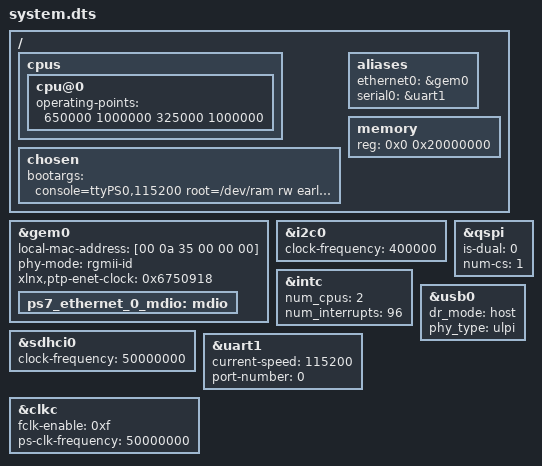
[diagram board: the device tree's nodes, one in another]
/*
 * CAUTION: This file is automatically generated by Xilinx.
 * Version:  
 * Today is: Wed Jul  8 15:01:53 2015
*/


/dts-v1/;
/include/ "zynq-7000.dtsi"
/include/ "pl.dtsi"
/ {
	cpus {
		cpu@0 {
			operating-points = <650000 1000000 325000 1000000>;
		};
	};
	chosen {
		bootargs = "console=ttyPS0,115200 root=/dev/ram rw earlyprintk";
	};
	aliases {
		ethernet0 = &gem0;
		serial0 = &uart1;
	};
	memory {
		device_type = "memory";
		reg = <0x0 0x20000000>;
	};
};
&gem0 {
	local-mac-address = [00 0a 35 00 00 00];
	phy-mode = "rgmii-id";
	status = "okay";
	xlnx,ptp-enet-clock = <0x6750918>;
	ps7_ethernet_0_mdio: mdio {
		#address-cells = <1>;
		#size-cells = <0>;
	};
};
&i2c0 {
	clock-frequency = <400000>;
	status = "okay";
};
&intc {
	num_cpus = <2>;
	num_interrupts = <96>;
};
&qspi {
	is-dual = <0>;
	num-cs = <1>;
	status = "okay";
};
&sdhci0 {
	clock-frequency = <50000000>;
	status = "okay";
};
&uart1 {
	current-speed = <115200>;
	device_type = "serial";
	port-number = <0>;
	status = "okay";
};
&usb0 {
	dr_mode = "host";
	phy_type = "ulpi";
	status = "okay";
};
&clkc {
	fclk-enable = <0xf>;
	ps-clk-frequency = <50000000>;
};
